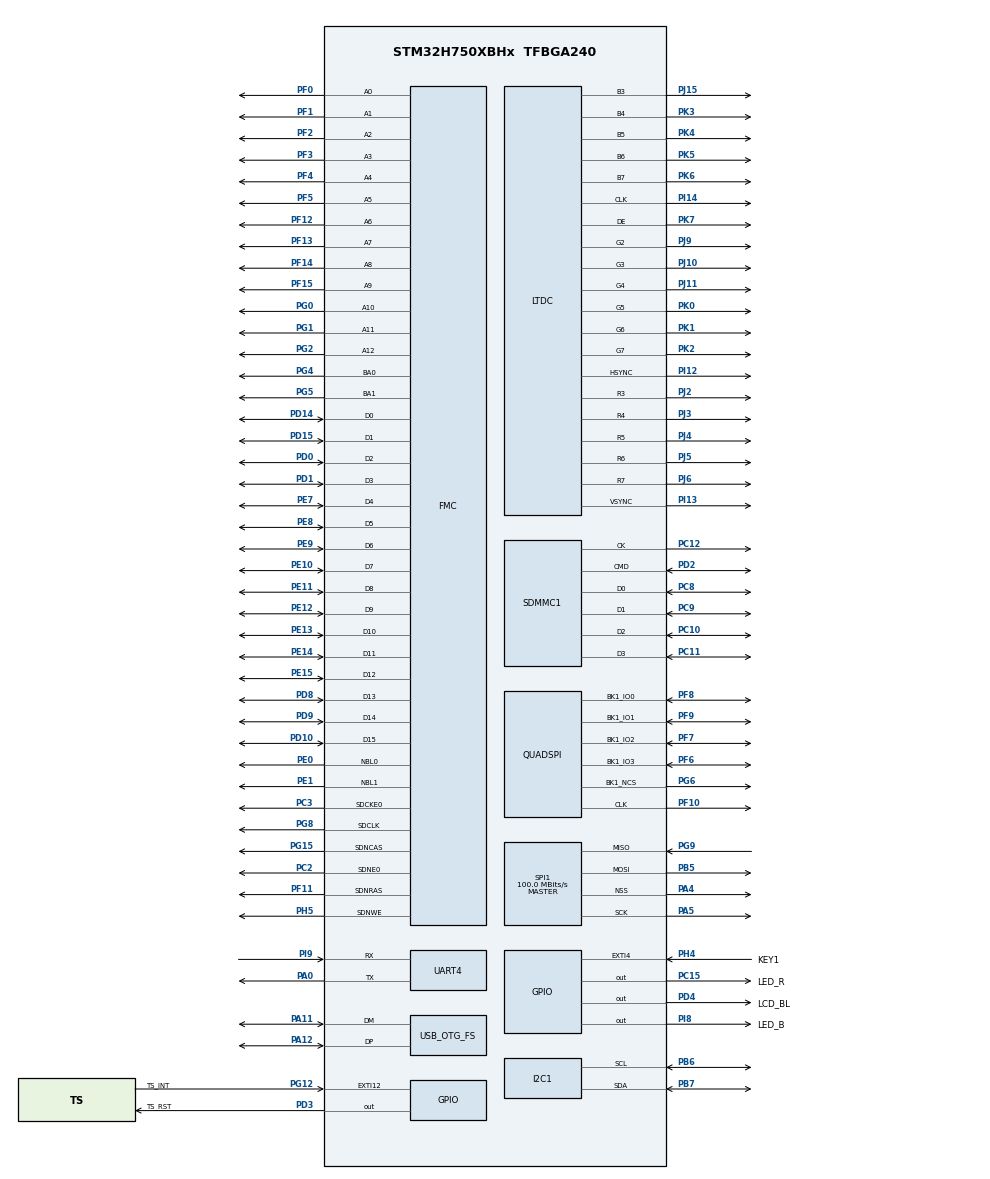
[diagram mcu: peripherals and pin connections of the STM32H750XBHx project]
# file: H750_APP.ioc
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CORTEX_M7.CPU_DCache=Disabled
CORTEX_M7.CPU_ICache=Disabled
DMA2D.ColorMode=DMA2D_OUTPUT_RGB565
FMC.CASLatency1=FMC_SDRAM_CAS_LATENCY_2
FMC.ColumnBitsNumber1=FMC_SDRAM_COLUMN_BITS_NUM_9
FMC.ExitSelfRefreshDelay1=8
FMC.LoadToActiveDelay1=2
FMC.RCDDelay1=2
FMC.RPDelay1=2
FMC.RPDelay2=2
FMC.ReadBurst1=FMC_SDRAM_RBURST_ENABLE
FMC.ReadPipeDelay1=FMC_SDRAM_RPIPE_DELAY_0
FMC.RowCycleDelay1=6
FMC.RowCycleDelay2=6
FMC.SDClockPeriod1=FMC_SDRAM_CLOCK_PERIOD_2
FMC.SDClockPeriod2=FMC_SDRAM_CLOCK_PERIOD_2
FMC.SelfRefreshTime1=6
FMC.WriteRecoveryTime1=4
LTDC.ActiveH=600
LTDC.ActiveW=1024
LTDC.Alpha_L0=0xFF
LTDC.Blue_L0=0
LTDC.FBStartAdress_L0=0xC0000000
LTDC.FBStartAdress_L1=0xc0100000
LTDC.HBP=88
LTDC.HFP=40
LTDC.HSync=1
LTDC.ImageHeight_L0=160
LTDC.ImageHeight_L1=480
LTDC.ImageWidth_L0=128
LTDC.Layers=0
LTDC.PixelFormat_L0=LTDC_PIXEL_FORMAT_RGB565
LTDC.VBP=32
LTDC.VFP=13
LTDC.VSync=1
LTDC.WindowX1_L0=400
LTDC.WindowX1_L1=800
LTDC.WindowY1_L0=200
LTDC.WindowY1_L1=480
Mcu.Family=STM32H7
Mcu.Name=STM32H750XBHx
Mcu.Package=TFBGA240
NVIC.DMA2D_IRQn=true\:0\:0\:false\:false\:true\:true\:true
NVIC.LTDC_ER_IRQn=true\:0\:0\:false\:false\:true\:true\:true
NVIC.LTDC_IRQn=true\:0\:0\:false\:false\:true\:true\:true
NVIC.PriorityGroup=NVIC_PRIORITYGROUP_4
NVIC.SDMMC1_IRQn=true\:0\:0\:false\:false\:true\:true\:true
NVIC.TIM6_DAC_IRQn=true\:0\:0\:false\:false\:true\:false\:true
NVIC.TimeBase=TIM6_DAC_IRQn
NVIC.TimeBaseIP=TIM6
NVIC.UART4_IRQn=true\:0\:0\:false\:false\:true\:true\:true
PA0.Mode=Asynchronous
PA0.Signal=UART4_TX
PA11.Mode=Device_Only
PA11.Signal=USB_OTG_FS_DM
PA12.Mode=Device_Only
PA12.Signal=USB_OTG_FS_DP
PA4.Mode=NSS_Signal_Hard_Output
PA4.Signal=SPI1_NSS
PA5.Mode=Full_Duplex_Master
PA5.Signal=SPI1_SCK
PB5.Mode=Full_Duplex_Master
PB5.Signal=SPI1_MOSI
PB6.Mode=I2C
PB6.Signal=I2C1_SCL
PB7.Mode=I2C
PB7.Signal=I2C1_SDA
PC10.Mode=SD_4_bits_Wide_bus
PC10.Signal=SDMMC1_D2
PC11.Mode=SD_4_bits_Wide_bus
PC11.Signal=SDMMC1_D3
PC12.Mode=SD_4_bits_Wide_bus
PC12.Signal=SDMMC1_CK
PC15-OSC32_OUT\ (OSC32_OUT).GPIO_Label=LED_R
PC15-OSC32_OUT\ (OSC32_OUT).GPIO_ModeDefaultOutputPP=GPIO_MODE_OUTPUT_PP
PC15-OSC32_OUT\ (OSC32_OUT).GPIO_PuPd=GPIO_PULLUP
PC15-OSC32_OUT\ (OSC32_OUT).GPIO_Speed=GPIO_SPEED_FREQ_LOW
PC15-OSC32_OUT\ (OSC32_OUT).PinState=GPIO_PIN_SET
PC15-OSC32_OUT\ (OSC32_OUT).Signal=GPIO_Output
PC2.Mode=SdramChipSelect1_1
PC2.Signal=FMC_SDNE0
PC3.Mode=SdramChipSelect1_1
PC3.Signal=FMC_SDCKE0
PC8.Mode=SD_4_bits_Wide_bus
PC8.Signal=SDMMC1_D0
PC9.Mode=SD_4_bits_Wide_bus
PC9.Signal=SDMMC1_D1
PD0.Signal=FMC_D2_DA2
PD1.Signal=FMC_D3_DA3
PD10.Signal=FMC_D15_DA15
PD14.Signal=FMC_D0_DA0
PD15.Signal=FMC_D1_DA1
PD2.Mode=SD_4_bits_Wide_bus
PD2.Signal=SDMMC1_CMD
PD3.GPIO_Label=TS_RST
PD3.GPIO_ModeDefaultOutputPP=GPIO_MODE_OUTPUT_PP
PD3.GPIO_PuPd=GPIO_PULLUP
PD3.GPIO_Speed=GPIO_SPEED_FREQ_LOW
PD3.PinState=GPIO_PIN_SET
PD3.Signal=GPIO_Output
PD4.GPIO_Label=LCD_BL
PD4.GPIO_ModeDefaultOutputPP=GPIO_MODE_OUTPUT_PP
PD4.GPIO_PuPd=GPIO_PULLUP
PD4.GPIO_Speed=GPIO_SPEED_FREQ_VERY_HIGH
PD4.PinState=GPIO_PIN_SET
PD4.Signal=GPIO_Output
PD8.Signal=FMC_D13_DA13
PD9.Signal=FMC_D14_DA14
PE0.Signal=FMC_NBL0
PE1.Signal=FMC_NBL1
PE10.Signal=FMC_D7_DA7
PE11.Signal=FMC_D8_DA8
PE12.Signal=FMC_D9_DA9
PE13.Signal=FMC_D10_DA10
PE14.Signal=FMC_D11_DA11
PE15.Signal=FMC_D12_DA12
PE7.Signal=FMC_D4_DA4
PE8.Signal=FMC_D5_DA5
PE9.Signal=FMC_D6_DA6
PF0.Signal=FMC_A0
PF1.Signal=FMC_A1
PF10.GPIO_Speed=GPIO_SPEED_FREQ_VERY_HIGH
PF10.Mode=Single Bank 1
PF10.Signal=QUADSPI_CLK
PF11.Signal=FMC_SDNRAS
PF12.Signal=FMC_A6
PF13.Signal=FMC_A7
PF14.Signal=FMC_A8
PF15.Signal=FMC_A9
PF2.Signal=FMC_A2
PF3.Signal=FMC_A3
PF4.Signal=FMC_A4
PF5.Signal=FMC_A5
PF6.GPIO_Speed=GPIO_SPEED_FREQ_VERY_HIGH
PF6.Mode=Single Bank 1
PF6.Signal=QUADSPI_BK1_IO3
PF7.GPIO_Speed=GPIO_SPEED_FREQ_VERY_HIGH
PF7.Mode=Single Bank 1
PF7.Signal=QUADSPI_BK1_IO2
PF8.GPIO_Speed=GPIO_SPEED_FREQ_VERY_HIGH
PF8.Mode=Single Bank 1
PF8.Signal=QUADSPI_BK1_IO0
PF9.GPIO_Speed=GPIO_SPEED_FREQ_VERY_HIGH
PF9.Mode=Single Bank 1
PF9.Signal=QUADSPI_BK1_IO1
PG0.Signal=FMC_A10
PG1.Signal=FMC_A11
PG12.GPIO_Label=TS_INT
PG12.GPIO_ModeDefaultEXTI=GPIO_MODE_IT_RISING_FALLING
PG12.GPIO_PuPd=GPIO_PULLUP
PG12.Signal=GPXTI12
PG15.Signal=FMC_SDNCAS
PG2.Signal=FMC_A12
PG4.Signal=FMC_A14_BA0
PG5.Signal=FMC_A15_BA1
PG6.GPIO_Speed=GPIO_SPEED_FREQ_VERY_HIGH
PG6.Mode=Single Bank 1
PG6.Signal=QUADSPI_BK1_NCS
PG8.Signal=FMC_SDCLK
PG9.Mode=Full_Duplex_Master
PG9.Signal=SPI1_MISO
PH0-OSC_IN\ (PH0).Mode=HSE-External-Oscillator
PH0-OSC_IN\ (PH0).Signal=RCC_OSC_IN
PH1-OSC_OUT\ (PH1).Mode=HSE-External-Oscillator
PH1-OSC_OUT\ (PH1).Signal=RCC_OSC_OUT
PH4.GPIO_Label=KEY1
PH4.GPIO_ModeDefaultEXTI=GPIO_MODE_IT_RISING_FALLING
PH4.GPIO_PuPd=GPIO_NOPULL
PH4.Signal=GPXTI4
PH5.Signal=FMC_SDNWE
PI12.GPIO_Speed=GPIO_SPEED_FREQ_VERY_HIGH
PI12.Mode=RGB565
PI12.Signal=LTDC_HSYNC
PI13.GPIO_Speed=GPIO_SPEED_FREQ_VERY_HIGH
PI13.Mode=RGB565
PI13.Signal=LTDC_VSYNC
PI14.GPIO_Speed=GPIO_SPEED_FREQ_VERY_HIGH
PI14.Mode=RGB565
PI14.Signal=LTDC_CLK
PI15.GPIO_Speed=GPIO_SPEED_FREQ_VERY_HIGH
PI15.Signal=LTDC_R0
PI8.GPIO_Label=LED_B
PI8.GPIO_ModeDefaultOutputPP=GPIO_MODE_OUTPUT_PP
PI8.GPIO_PuPd=GPIO_PULLUP
PI8.GPIO_Speed=GPIO_SPEED_FREQ_LOW
PI8.PinState=GPIO_PIN_SET
PI8.Signal=GPIO_Output
PI9.Mode=Asynchronous
PI9.Signal=UART4_RX
PJ0.GPIO_Speed=GPIO_SPEED_FREQ_VERY_HIGH
PJ0.Signal=LTDC_R1
PJ1.GPIO_Speed=GPIO_SPEED_FREQ_VERY_HIGH
PJ1.Signal=LTDC_R2
PJ10.GPIO_Speed=GPIO_SPEED_FREQ_VERY_HIGH
PJ10.Mode=RGB565
PJ10.Signal=LTDC_G3
PJ11.GPIO_Speed=GPIO_SPEED_FREQ_VERY_HIGH
PJ11.Mode=RGB565
PJ11.Signal=LTDC_G4
PJ12.GPIO_Speed=GPIO_SPEED_FREQ_VERY_HIGH
PJ12.Signal=LTDC_B0
PJ13.GPIO_Speed=GPIO_SPEED_FREQ_VERY_HIGH
PJ13.Signal=LTDC_B1
PJ14.GPIO_Speed=GPIO_SPEED_FREQ_VERY_HIGH
PJ14.Signal=LTDC_B2
PJ15.GPIO_Speed=GPIO_SPEED_FREQ_VERY_HIGH
PJ15.Mode=RGB565
PJ15.Signal=LTDC_B3
PJ2.GPIO_Speed=GPIO_SPEED_FREQ_VERY_HIGH
PJ2.Mode=RGB565
PJ2.Signal=LTDC_R3
PJ3.GPIO_Speed=GPIO_SPEED_FREQ_VERY_HIGH
PJ3.Mode=RGB565
PJ3.Signal=LTDC_R4
PJ4.GPIO_Speed=GPIO_SPEED_FREQ_VERY_HIGH
PJ4.Mode=RGB565
PJ4.Signal=LTDC_R5
PJ5.GPIO_Speed=GPIO_SPEED_FREQ_VERY_HIGH
PJ5.Mode=RGB565
PJ5.Signal=LTDC_R6
PJ6.GPIO_Speed=GPIO_SPEED_FREQ_VERY_HIGH
PJ6.Mode=RGB565
PJ6.Signal=LTDC_R7
PJ7.GPIO_Speed=GPIO_SPEED_FREQ_VERY_HIGH
PJ7.Signal=LTDC_G0
PJ8.GPIO_Speed=GPIO_SPEED_FREQ_VERY_HIGH
PJ8.Signal=LTDC_G1
PJ9.GPIO_Speed=GPIO_SPEED_FREQ_VERY_HIGH
PJ9.Mode=RGB565
PJ9.Signal=LTDC_G2
PK0.GPIO_Speed=GPIO_SPEED_FREQ_VERY_HIGH
PK0.Mode=RGB565
PK0.Signal=LTDC_G5
PK1.GPIO_Speed=GPIO_SPEED_FREQ_VERY_HIGH
PK1.Mode=RGB565
PK1.Signal=LTDC_G6
PK2.GPIO_Speed=GPIO_SPEED_FREQ_VERY_HIGH
PK2.Mode=RGB565
PK2.Signal=LTDC_G7
PK3.GPIO_Speed=GPIO_SPEED_FREQ_VERY_HIGH
PK3.Mode=RGB565
PK3.Signal=LTDC_B4
PK4.GPIO_Speed=GPIO_SPEED_FREQ_VERY_HIGH
PK4.Mode=RGB565
PK4.Signal=LTDC_B5
PK5.GPIO_Speed=GPIO_SPEED_FREQ_VERY_HIGH
PK5.Mode=RGB565
PK5.Signal=LTDC_B6
PK6.GPIO_Speed=GPIO_SPEED_FREQ_VERY_HIGH
PK6.Mode=RGB565
PK6.Signal=LTDC_B7
PK7.GPIO_Speed=GPIO_SPEED_FREQ_VERY_HIGH
PK7.Mode=RGB565
PK7.Signal=LTDC_DE
ProjectManager.HeapSize=0x200
ProjectManager.StackSize=0x400
ProjectManager.TargetToolchain=STM32CubeIDE
QUADSPI.ChipSelectHighTime=QSPI_CS_HIGH_TIME_5_CYCLE
QUADSPI.ClockPrescaler=1
QUADSPI.FifoThreshold=4
QUADSPI.FlashSize=22
QUADSPI.SampleShifting=QSPI_SAMPLE_SHIFTING_HALFCYCLE
RCC.ADCFreq_Value=400000000
RCC.APB1Freq_Value=120000000
RCC.APB2Freq_Value=120000000
RCC.APB3Freq_Value=120000000
RCC.APB4Freq_Value=120000000
RCC.CortexFreq_Value=480000000
RCC.D1PPRE=RCC_APB3_DIV2
RCC.D2PPRE1=RCC_APB1_DIV2
RCC.D2PPRE2=RCC_APB2_DIV2
RCC.D3PPRE=RCC_APB4_DIV2
RCC.DIVM1=5
RCC.DIVM2=2
RCC.DIVM3=5
RCC.DIVN1=192
RCC.DIVN2=64
RCC.DIVN3=160
RCC.DIVP3=8
RCC.DIVQ3=8
RCC.DIVR2=4
RCC.DIVR3=24
RCC.HCLKFreq_Value=240000000
RCC.HPRE=RCC_HCLK_DIV2
RCC.I2C123CLockSelection=RCC_I2C123CLKSOURCE_HSI
RCC.PLLFRACN=0
RCC.PLLSourceVirtual=RCC_PLLSOURCE_HSE
RCC.SPI123CLockSelection=RCC_SPI123CLKSOURCE_PLL2
RCC.SYSCLKFreq_VALUE=480000000
RCC.SYSCLKSource=RCC_SYSCLKSOURCE_PLLCLK
RCC.USBCLockSelection=RCC_USBCLKSOURCE_HSI48
RCC.USBFreq_Value=48000000
SDMMC1.TransceiverPresent=SDMMC_TRANSCEIVER_NOT_PRESENT
SH.FMC_A0.0=FMC_A0,13b-sda1
SH.FMC_A1.0=FMC_A1,13b-sda1
SH.FMC_A10.0=FMC_A10,13b-sda1
SH.FMC_A11.0=FMC_A11,13b-sda1
SH.FMC_A12.0=FMC_A12,13b-sda1
SH.FMC_A14_BA0.0=FMC_BA0,FourSdramBanks1
SH.FMC_A15_BA1.0=FMC_BA1,FourSdramBanks1
SH.FMC_A2.0=FMC_A2,13b-sda1
SH.FMC_A3.0=FMC_A3,13b-sda1
SH.FMC_A4.0=FMC_A4,13b-sda1
SH.FMC_A5.0=FMC_A5,13b-sda1
SH.FMC_A6.0=FMC_A6,13b-sda1
SH.FMC_A7.0=FMC_A7,13b-sda1
SH.FMC_A8.0=FMC_A8,13b-sda1
SH.FMC_A9.0=FMC_A9,13b-sda1
SH.FMC_D0_DA0.0=FMC_D0,sd-16b-d1
SH.FMC_D10_DA10.0=FMC_D10,sd-16b-d1
SH.FMC_D11_DA11.0=FMC_D11,sd-16b-d1
SH.FMC_D12_DA12.0=FMC_D12,sd-16b-d1
SH.FMC_D13_DA13.0=FMC_D13,sd-16b-d1
SH.FMC_D14_DA14.0=FMC_D14,sd-16b-d1
SH.FMC_D15_DA15.0=FMC_D15,sd-16b-d1
SH.FMC_D1_DA1.0=FMC_D1,sd-16b-d1
SH.FMC_D2_DA2.0=FMC_D2,sd-16b-d1
SH.FMC_D3_DA3.0=FMC_D3,sd-16b-d1
SH.FMC_D4_DA4.0=FMC_D4,sd-16b-d1
SH.FMC_D5_DA5.0=FMC_D5,sd-16b-d1
SH.FMC_D6_DA6.0=FMC_D6,sd-16b-d1
SH.FMC_D7_DA7.0=FMC_D7,sd-16b-d1
SH.FMC_D8_DA8.0=FMC_D8,sd-16b-d1
SH.FMC_D9_DA9.0=FMC_D9,sd-16b-d1
SH.FMC_NBL0.0=FMC_NBL0,Sd2ByteEnable1
SH.FMC_NBL1.0=FMC_NBL1,Sd2ByteEnable1
SH.FMC_SDCLK.0=FMC_SDCLK,13b-sda1
SH.FMC_SDNCAS.0=FMC_SDNCAS,13b-sda1
SH.FMC_SDNRAS.0=FMC_SDNRAS,13b-sda1
SH.FMC_SDNWE.0=FMC_SDNWE,13b-sda1
SPI1.BaudRatePrescaler=SPI_BAUDRATEPRESCALER_4
SPI1.CalculateBaudRate=100.0 MBits/s
SPI1.Direction=SPI_DIRECTION_2LINES
SPI1.Mode=SPI_MODE_MASTER
SPI1.VirtualNSS=VM_NSSHARD
SPI1.VirtualType=VM_MASTER
USB_OTG_FS.VirtualMode=Device_Only
VP_CRC_VS_CRC.Mode=CRC_Activate
VP_DMA2D_VS_DMA2D.Mode=DMA2D_Activate
VP_SYS_VS_tim6.Mode=TIM6
board=custom

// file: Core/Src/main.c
/* USER CODE BEGIN Header */
/**
  ******************************************************************************
  * @file           : main.c
  * @brief          : Main program body
  ******************************************************************************
  * @attention
  *
  * <h2><center>&copy; Copyright (c) 2021 STMicroelectronics.
  * All rights reserved.</center></h2>
  *
  * This software component is licensed by ST under BSD 3-Clause license,
  * the "License"; You may not use this file except in compliance with the
  * License. You may obtain a copy of the License at:
  *                        opensource.org/licenses/BSD-3-Clause
  *
  ******************************************************************************
  */
/* USER CODE END Header */
#include "main.h"
#include "crc.h"
#include "dma2d.h"
#include "i2c.h"
#include "ltdc.h"
#include "quadspi.h"
#include "sdmmc.h"
#include "spi.h"
#include "usart.h"
#include "usb_otg.h"
#include "gpio.h"
#include "fmc.h"

/* USER CODE BEGIN Includes */
#include "drv_sdram.h"
#include "tx_entry_main.h"
#include "stm32h7xx.h"
static int vtor_config(void)
{
    /* Vector Table Relocation in Internal QSPI_FLASH */
    SCB->VTOR = QSPI_BASE;
    return 0;
}
/* USER CODE END Includes */

void SystemClock_Config(void);

int main(void)
{
  /* USER CODE BEGIN 1 */
  vtor_config();
  /* USER CODE END 1 */

  /* MCU Configuration--------------------------------------------------------*/

  /* Reset of all peripherals, Initializes the Flash interface and the Systick. */
  HAL_Init();

  /* Configure the system clock */
  SystemClock_Config();

  /* Initialize all configured peripherals */
  MX_GPIO_Init();
  MX_UART4_Init();
  MX_I2C1_Init();
  MX_LTDC_Init();
  MX_SDMMC1_SD_Init();
  MX_FMC_Init();
  MX_SPI1_Init();
//  MX_QUADSPI_Init();
  MX_DMA2D_Init();
  MX_USB_OTG_FS_PCD_Init();
  MX_CRC_Init();
  /* USER CODE BEGIN 2 */

  SDRAM_Init();
  threadx_entry_main();

  /* USER CODE END 2 */

  /* Infinite loop */
  while (1)
  {

  }
}

void SystemClock_Config(void)
{
  RCC_OscInitTypeDef RCC_OscInitStruct = {0};
  RCC_ClkInitTypeDef RCC_ClkInitStruct = {0};
  RCC_PeriphCLKInitTypeDef PeriphClkInitStruct = {0};

  /** Supply configuration update enable
  */
  HAL_PWREx_ConfigSupply(PWR_LDO_SUPPLY);
  /** Configure the main internal regulator output voltage
  */
  __HAL_PWR_VOLTAGESCALING_CONFIG(PWR_REGULATOR_VOLTAGE_SCALE0);

  while(!__HAL_PWR_GET_FLAG(PWR_FLAG_VOSRDY)) {}
  /** Macro to configure the PLL clock source
  */
  __HAL_RCC_PLL_PLLSOURCE_CONFIG(RCC_PLLSOURCE_HSE);
  /** Initializes the RCC Oscillators according to the specified parameters
  * in the RCC_OscInitTypeDef structure.
  */
  RCC_OscInitStruct.OscillatorType = RCC_OSCILLATORTYPE_HSI48|RCC_OSCILLATORTYPE_HSI
                              |RCC_OSCILLATORTYPE_HSE;
  RCC_OscInitStruct.HSEState = RCC_HSE_ON;
  RCC_OscInitStruct.HSIState = RCC_HSI_DIV1;
  RCC_OscInitStruct.HSICalibrationValue = RCC_HSICALIBRATION_DEFAULT;
  RCC_OscInitStruct.HSI48State = RCC_HSI48_ON;
  RCC_OscInitStruct.PLL.PLLState = RCC_PLL_ON;
  RCC_OscInitStruct.PLL.PLLSource = RCC_PLLSOURCE_HSE;
  RCC_OscInitStruct.PLL.PLLM = 5;
  RCC_OscInitStruct.PLL.PLLN = 192;
  RCC_OscInitStruct.PLL.PLLP = 2;
  RCC_OscInitStruct.PLL.PLLQ = 2;
  RCC_OscInitStruct.PLL.PLLR = 2;
  RCC_OscInitStruct.PLL.PLLRGE = RCC_PLL1VCIRANGE_2;
  RCC_OscInitStruct.PLL.PLLVCOSEL = RCC_PLL1VCOWIDE;
  RCC_OscInitStruct.PLL.PLLFRACN = 0;
  if (HAL_RCC_OscConfig(&RCC_OscInitStruct) != HAL_OK)
  {
    Error_Handler();
  }
  /** Initializes the CPU, AHB and APB buses clocks
  */
  RCC_ClkInitStruct.ClockType = RCC_CLOCKTYPE_HCLK|RCC_CLOCKTYPE_SYSCLK
                              |RCC_CLOCKTYPE_PCLK1|RCC_CLOCKTYPE_PCLK2
                              |RCC_CLOCKTYPE_D3PCLK1|RCC_CLOCKTYPE_D1PCLK1;
  RCC_ClkInitStruct.SYSCLKSource = RCC_SYSCLKSOURCE_PLLCLK;
  RCC_ClkInitStruct.SYSCLKDivider = RCC_SYSCLK_DIV1;
  RCC_ClkInitStruct.AHBCLKDivider = RCC_HCLK_DIV2;
  RCC_ClkInitStruct.APB3CLKDivider = RCC_APB3_DIV2;
  RCC_ClkInitStruct.APB1CLKDivider = RCC_APB1_DIV2;
  RCC_ClkInitStruct.APB2CLKDivider = RCC_APB2_DIV2;
  RCC_ClkInitStruct.APB4CLKDivider = RCC_APB4_DIV2;

  if (HAL_RCC_ClockConfig(&RCC_ClkInitStruct, FLASH_LATENCY_4) != HAL_OK)
  {
    Error_Handler();
  }
  PeriphClkInitStruct.PeriphClockSelection = RCC_PERIPHCLK_LTDC|RCC_PERIPHCLK_UART4
                              |RCC_PERIPHCLK_SPI1|RCC_PERIPHCLK_SDMMC
                              |RCC_PERIPHCLK_I2C1|RCC_PERIPHCLK_USB
                              |RCC_PERIPHCLK_QSPI|RCC_PERIPHCLK_FMC;
  PeriphClkInitStruct.PLL2.PLL2M = 2;
  PeriphClkInitStruct.PLL2.PLL2N = 64;
  PeriphClkInitStruct.PLL2.PLL2P = 2;
  PeriphClkInitStruct.PLL2.PLL2Q = 2;
  PeriphClkInitStruct.PLL2.PLL2R = 4;
  PeriphClkInitStruct.PLL2.PLL2RGE = RCC_PLL2VCIRANGE_3;
  PeriphClkInitStruct.PLL2.PLL2VCOSEL = RCC_PLL2VCOWIDE;
  PeriphClkInitStruct.PLL2.PLL2FRACN = 0;
  PeriphClkInitStruct.PLL3.PLL3M = 5;
  PeriphClkInitStruct.PLL3.PLL3N = 160;
  PeriphClkInitStruct.PLL3.PLL3P = 8;
  PeriphClkInitStruct.PLL3.PLL3Q = 8;
  PeriphClkInitStruct.PLL3.PLL3R = 24;
  PeriphClkInitStruct.PLL3.PLL3RGE = RCC_PLL3VCIRANGE_2;
  PeriphClkInitStruct.PLL3.PLL3VCOSEL = RCC_PLL3VCOWIDE;
  PeriphClkInitStruct.PLL3.PLL3FRACN = 0;
  PeriphClkInitStruct.FmcClockSelection = RCC_FMCCLKSOURCE_D1HCLK;
  PeriphClkInitStruct.QspiClockSelection = RCC_QSPICLKSOURCE_D1HCLK;
  PeriphClkInitStruct.SdmmcClockSelection = RCC_SDMMCCLKSOURCE_PLL;
  PeriphClkInitStruct.Spi123ClockSelection = RCC_SPI123CLKSOURCE_PLL2;
  PeriphClkInitStruct.Usart234578ClockSelection = RCC_USART234578CLKSOURCE_D2PCLK1;
  PeriphClkInitStruct.I2c123ClockSelection = RCC_I2C123CLKSOURCE_HSI;
  PeriphClkInitStruct.UsbClockSelection = RCC_USBCLKSOURCE_HSI48;
  if (HAL_RCCEx_PeriphCLKConfig(&PeriphClkInitStruct) != HAL_OK)
  {
    Error_Handler();
  }
  /** Enable USB Voltage detector
  */
  HAL_PWREx_EnableUSBVoltageDetector();
}

/* USER CODE BEGIN 4 */
int __io_putchar(int ch)
{
    HAL_UART_Transmit(&huart4, (uint8_t*)&ch, 1, HAL_MAX_DELAY);
    return ch;
}
/* USER CODE END 4 */

void HAL_TIM_PeriodElapsedCallback(TIM_HandleTypeDef *htim)
{
  if (htim->Instance == TIM6) {
    HAL_IncTick();
  }
}

void Error_Handler(void)
{
}

/************************ (C) COPYRIGHT STMicroelectronics *****END OF FILE****/
